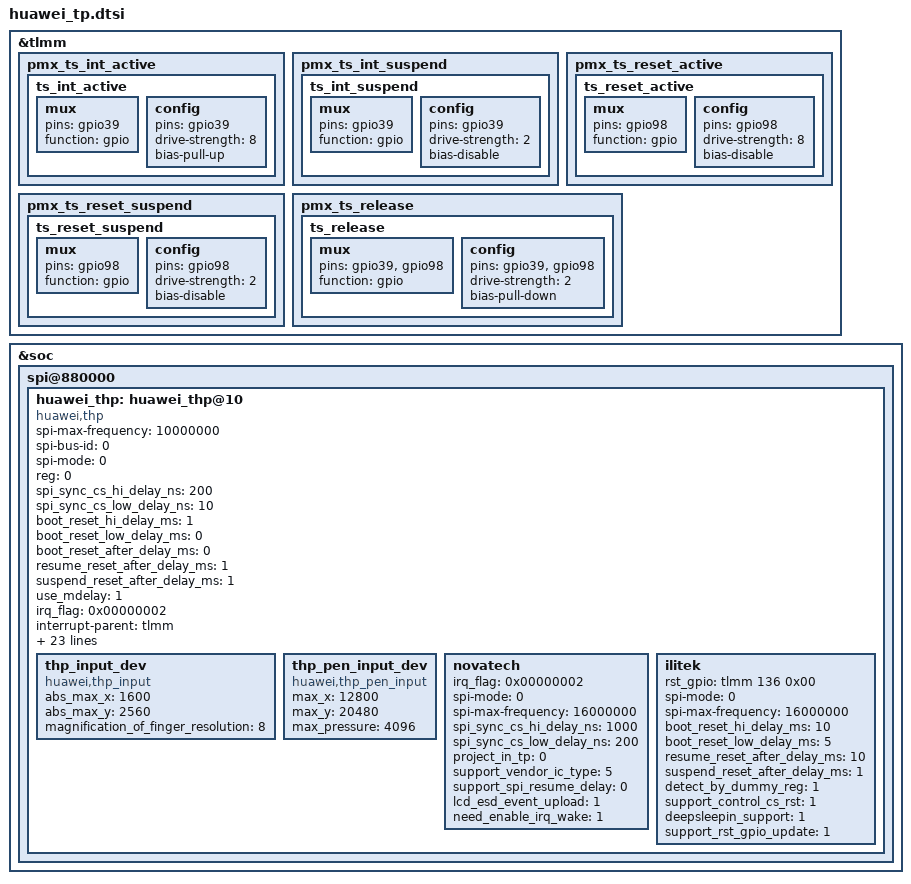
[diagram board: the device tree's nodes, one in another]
/* touch panel config */
&tlmm {
	pmx_ts_int_active {
		ts_int_active: ts_int_active {
			mux {
				pins = "gpio39";
				function = "gpio";
			};

			config {
				pins = "gpio39";
				drive-strength = <8>;
				bias-pull-up;
			};
		};
	};

	pmx_ts_int_suspend {
		ts_int_suspend: ts_int_suspend {
			mux {
				pins = "gpio39";
				function = "gpio";
			};

			config {
				pins = "gpio39";
				drive-strength = <2>;
				bias-disable;
			};
		};
	};

	pmx_ts_reset_active {
		ts_reset_active: ts_reset_active {
			mux {
				pins = "gpio98";
				function = "gpio";
			};

			config {
				pins = "gpio98";
				drive-strength = <8>;
				bias-disable;
			};
		};
	};

	pmx_ts_reset_suspend {
		ts_reset_suspend: ts_reset_suspend {
			mux {
				pins = "gpio98";
				function = "gpio";
			};

			config {
				pins = "gpio98";
				drive-strength = <2>;
				bias-disable;
			};
		};
	};

	pmx_ts_release {
		ts_release: ts_release {
			mux {
				pins = "gpio39", "gpio98";
				function = "gpio";
			};

			config {
				pins = "gpio39", "gpio98";
				drive-strength = <2>;
				bias-pull-down;
			};
		};
	};
};

&soc {
	spi@880000 {
		status = "ok";
		#address-cells = <1>;
		#size-cells = <0>;
		huawei_thp: huawei_thp@10 {
			compatible = "huawei,thp";
			/* SPI Config */
			spi-max-frequency = <10000000>;
			spi-bus-id = <0>;
			spi-mode = <0>;
			reg = <0>;
			spi_sync_cs_hi_delay_ns = <200>;
			spi_sync_cs_low_delay_ns = <10>;

			/* Timing */
			boot_reset_hi_delay_ms = <1>;
			boot_reset_low_delay_ms = <0>;
			boot_reset_after_delay_ms = <0>;
			resume_reset_after_delay_ms = <1>;
			suspend_reset_after_delay_ms = <1>;
			use_mdelay = <1>;

			/* GPIO Config */
			irq_flag = <0x00000002>;
			interrupt-parent = <&tlmm>;
			interrupts = <39 0>;
			rst_gpio = <&tlmm 98 0x00>;
			irq_gpio = <&tlmm 39 0x00>;
			cs_gpio = <&tlmm 43 0x00>;

			pinctrl-names = "default", "idle";
			pinctrl-0 = <&ts_int_active &ts_reset_active>;
			pinctrl-1 = <&ts_int_suspend &ts_reset_suspend>;

			/* Feature Config */
			support_pinctrl = <1>;
			pinctrl_init_enable = <1>;
			pt_station_test = <1>;
			proximity_support = <0>;
			hide_product_info_en = <1>;
			support_vendor_ic_type = <5>;
			pen_supported = <1>;
			pen_mt_enable_flag = <1>;
			support_gesture_mode = <1>;
			lcd_gesture_mode_support = <1>;
			support_stylus3_plam_suppression = <1>;
			send_bt_status_to_fw = <1>;
			send_adsorption_status_to_fw = <1>;
			supported_charger = <1>;
			lcd_esd_event_upload = <1>;
			need_enable_irq_wake = <1>;
			aptouch_daemon_version = <3>;

			thp_input_dev {
				compatible = "huawei,thp_input";
				abs_max_x = <1600>;
				abs_max_y = <2560>;
				magnification_of_finger_resolution = <8>;
			};
			thp_pen_input_dev {
				compatible = "huawei,thp_pen_input";
				max_x = <12800>;
				max_y = <20480>;
				max_pressure = <4096>;
			};
			novatech {
				irq_flag = <0x00000002>;
				spi-mode = <0>;
				spi-max-frequency = <16000000>;
				spi_sync_cs_hi_delay_ns = <1000>;
				spi_sync_cs_low_delay_ns = <200>;
				//change_spi_driving_force = <1>;
				project_in_tp = <0>;
				support_vendor_ic_type = <5>;
				support_spi_resume_delay = <0>;
				lcd_esd_event_upload = <1>;
				need_enable_irq_wake = <1>;
			};
			ilitek {
				rst_gpio = <&tlmm 136 0x00>;
				spi-mode = <0>;
				spi-max-frequency = <16000000>;
				boot_reset_hi_delay_ms = <10>;
				boot_reset_low_delay_ms = <5>;
				resume_reset_after_delay_ms = <10>;
				suspend_reset_after_delay_ms = <1>;
				detect_by_dummy_reg = <1>;
				support_control_cs_rst = <1>;
				deepsleepin_support = <1>;
				support_rst_gpio_update = <1>;
			};
		};
	};
};
